# MINI_UART register map
File version: 1
BCM2711 auxiliary mini UART (UART1)
Registers are read-write, no defined reset value unless marked. A register's access mark holds for its fields unless they carry their own. Offsets are from the block's base; lines under a group give offsets from that group; [hi:lo] are bit positions; {n}, {i} and the like mark numbered series; 'fields as' and 'values as' point back to an identical list; <NAME> marks a mode.

## Memory map
0x00000000 MINI_UART size 0x40

## MINI_UART
Base 0x00000000
0x00 IO — AUX_MU_IO_REG: a read takes the next byte of the receive FIFO, a write puts a byte in the transmit FIFO
  [7:0] DATA
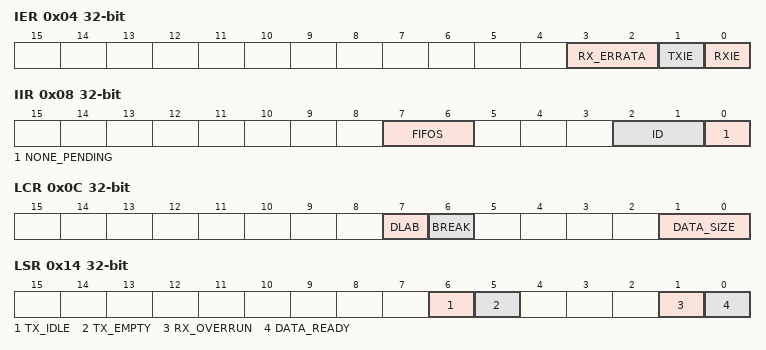
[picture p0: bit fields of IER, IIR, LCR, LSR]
0x04 IER — AUX_MU_IER_REG: interrupt enables
  [3:2] RX_ERRATA — Both 1 for the receive interrupt on silicon: ARM Peripherals marks them unused, the BCM2835 errata says the receive interrupt needs them; QEMU ignores them
  [1] TXIE — Interrupt while the transmit FIFO is empty
  [0] RXIE — Interrupt while the receive FIFO holds a byte
0x08 IIR — AUX_MU_IIR_REG: the pending interrupt; writing ID's bits 1 and 2 clears the receive and transmit FIFOs
  [7:6] FIFOS — Both FIFOs always enabled, reads 3
  [2:1] ID — 1 transmit FIFO empty, 2 receive FIFO holds a byte
  [0] NONE_PENDING — 0 while an interrupt is pending
0x0C LCR — AUX_MU_LCR_REG: line control
  [7] DLAB — Give the first two registers to the baud rate's bytes
  [6] BREAK — Hold the transmit line low
  [1:0] DATA_SIZE — 3 for eight-bit characters, 0 for seven
0x10 MCR — AUX_MU_MCR_REG: modem control
  [1] RTS — Drive the RTS line low
0x14 LSR ro — AUX_MU_LSR_REG: line status
  [6] TX_IDLE — The transmit FIFO is empty and the transmitter idle
  [5] TX_EMPTY — The transmit FIFO can take at least one byte
  [1] RX_OVERRUN — A byte arrived to a full receive FIFO; cleared by the read
  [0] DATA_READY — The receive FIFO holds at least one byte
0x18 MSR ro — AUX_MU_MSR_REG: modem status
  [4] CTS — The CTS line's state, inverted
0x1C SCRATCH — AUX_MU_SCRATCH: a byte of storage
  [7:0] VALUE
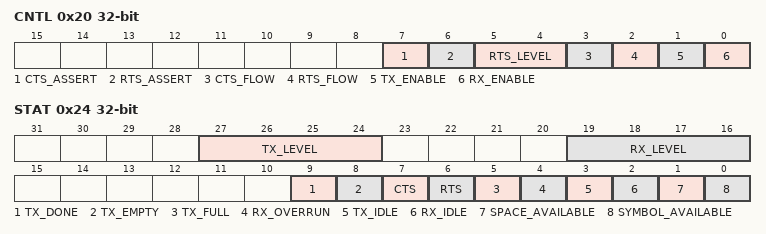
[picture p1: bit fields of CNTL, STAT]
0x20 CNTL — AUX_MU_CNTL_REG: receiver, transmitter and flow control
  [7] CTS_ASSERT, [6] RTS_ASSERT, [5:4] RTS_LEVEL, [3] CTS_FLOW, [2] RTS_FLOW, [1] TX_ENABLE, [0] RX_ENABLE
0x24 STAT ro — AUX_MU_STAT_REG: the FIFOs' and lines' state
  [27:24] TX_LEVEL, [19:16] RX_LEVEL, [9] TX_DONE, [8] TX_EMPTY, [7] CTS, [6] RTS, [5] TX_FULL, [4] RX_OVERRUN, [3] TX_IDLE, [2] RX_IDLE, [1] SPACE_AVAILABLE, [0] SYMBOL_AVAILABLE
0x28 BAUD — AUX_MU_BAUD_REG: the baud divisor, core clock / (8 * (BAUD + 1))
  [15:0] DIVISOR

## Notices in the file
Copyright (c) 2026, Stanislav Sedov <stas@deglitch.com>
SPDX-License-Identifier: BSD-2-Clause
